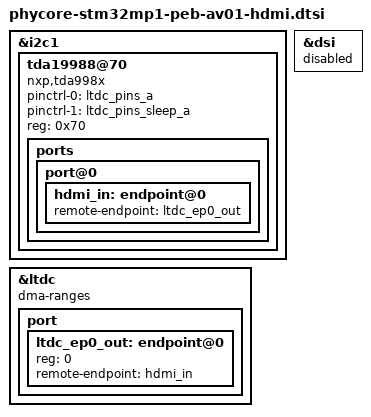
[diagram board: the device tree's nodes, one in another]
// SPDX-License-Identifier: (GPL-2.0+ OR BSD-3-Clause)
/*
 * Copyright (C) PHYTEC GmbH 2019 - All Rights Reserved
 * Author: Dom VOVARD <dom.vovard@linrt.com>.
 */

&i2c1 {
        tda19988@70 {
                compatible = "nxp,tda998x";
		pinctrl-names = "default", "sleep";
		pinctrl-0 = <&ltdc_pins_a>;
		pinctrl-1 = <&ltdc_pins_sleep_a>;
                reg = <0x70>;
                status = "okay";

                ports {
                        port@0 {
                                hdmi_in: endpoint@0 {
                                        remote-endpoint = <&ltdc_ep0_out>;
                                };
                        };
                };
        };
};

&ltdc {
        dma-ranges;
	status = "okay";

	port {
		#address-cells = <1>;
		#size-cells = <0>;

		ltdc_ep0_out: endpoint@0 {
			reg = <0>;
			remote-endpoint = <&hdmi_in>;
		};
	};
};

&dsi {
        status = "disabled";
};
